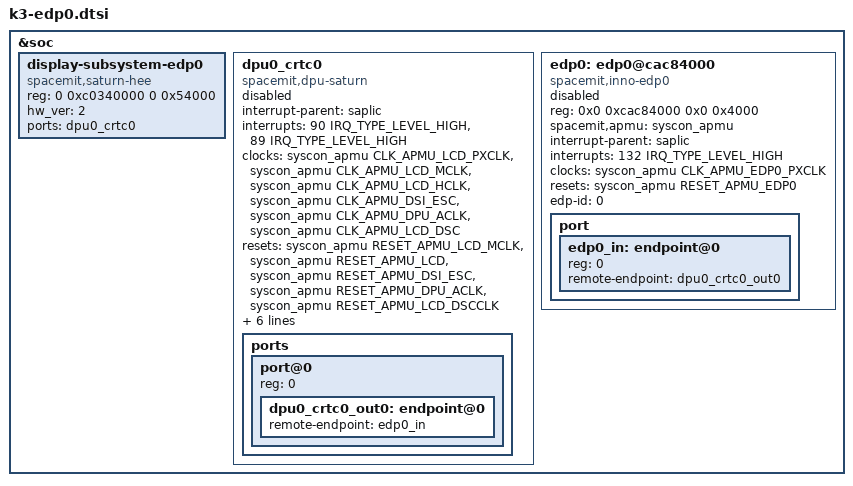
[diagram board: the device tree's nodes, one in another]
// SPDX-License-Identifier: (GPL-2.0 OR MIT)
/* Copyright (c) 2025 Spacemit, Inc */

&soc {
	display-subsystem-edp0 {
		compatible = "spacemit,saturn-hee";
		reg = <0 0xc0340000 0 0x54000>;
		hw_ver = <2>;
		ports = <&dpu0_crtc0>;
	};

	dpu0_crtc0: dpu0_crtc0 {
		compatible = "spacemit,dpu-saturn";
		interrupt-parent = <&saplic>;
		interrupts = <90 IRQ_TYPE_LEVEL_HIGH>,
			     <89 IRQ_TYPE_LEVEL_HIGH>;
		interrupt-names = "ONLINE_IRQ",
				  "OFFLINE_IRQ";
		clocks = <&syscon_apmu CLK_APMU_LCD_PXCLK>,
			<&syscon_apmu CLK_APMU_LCD_MCLK>,
			<&syscon_apmu CLK_APMU_LCD_HCLK>,
			<&syscon_apmu CLK_APMU_DSI_ESC>,
			<&syscon_apmu CLK_APMU_DPU_ACLK>,
			<&syscon_apmu CLK_APMU_LCD_DSC>;
		clock-names = "pxclk", "mclk", "hclk", "escclk", "aclk", "dscclk";
		resets = <&syscon_apmu RESET_APMU_LCD_MCLK>,
			<&syscon_apmu RESET_APMU_LCD>,
			<&syscon_apmu RESET_APMU_DSI_ESC>,
			<&syscon_apmu RESET_APMU_DPU_ACLK>,
			<&syscon_apmu RESET_APMU_LCD_DSCCLK>;
		reset-names= "mclk_reset", "lcd_reset", "esc_reset", "aclk_reset", "dsc_reset";
		power-domains = <&power K3_PMU_LCD0_PWR_DOMAIN>;
		pipeline-id = <1>;
		is_edp = <1>;
		dpu-id = <0>;
		ip = "spacemit-saturn";
		spacemit-dpu-min-mclk = <40960000>;
		status = "disabled";

		ports {
			#address-cells = <1>;
			#size-cells = <0>;

			port@0 {
				reg = <0>;
				dpu0_crtc0_out0: endpoint@0 {
					remote-endpoint = <&edp0_in>;
				};
			};
		};
	};

	edp0: edp0@cac84000 {
		compatible = "spacemit,inno-edp0";
		reg = <0x0 0xcac84000 0x0 0x4000>;
		spacemit,apmu = <&syscon_apmu>;
		interrupt-parent = <&saplic>;
		interrupts = <132 IRQ_TYPE_LEVEL_HIGH>;
		clocks = <&syscon_apmu CLK_APMU_EDP0_PXCLK>;
		clock-names = "pxclk";
		resets = <&syscon_apmu RESET_APMU_EDP0>;
		reset-names= "reset";
		edp-id = <0>;
		status = "disabled";

		port {
			#address-cells = <1>;
			#size-cells = <0>;

			edp0_in: endpoint@0 {
				reg = <0>;
				remote-endpoint = <&dpu0_crtc0_out0>;
			};
		};
	};

};
